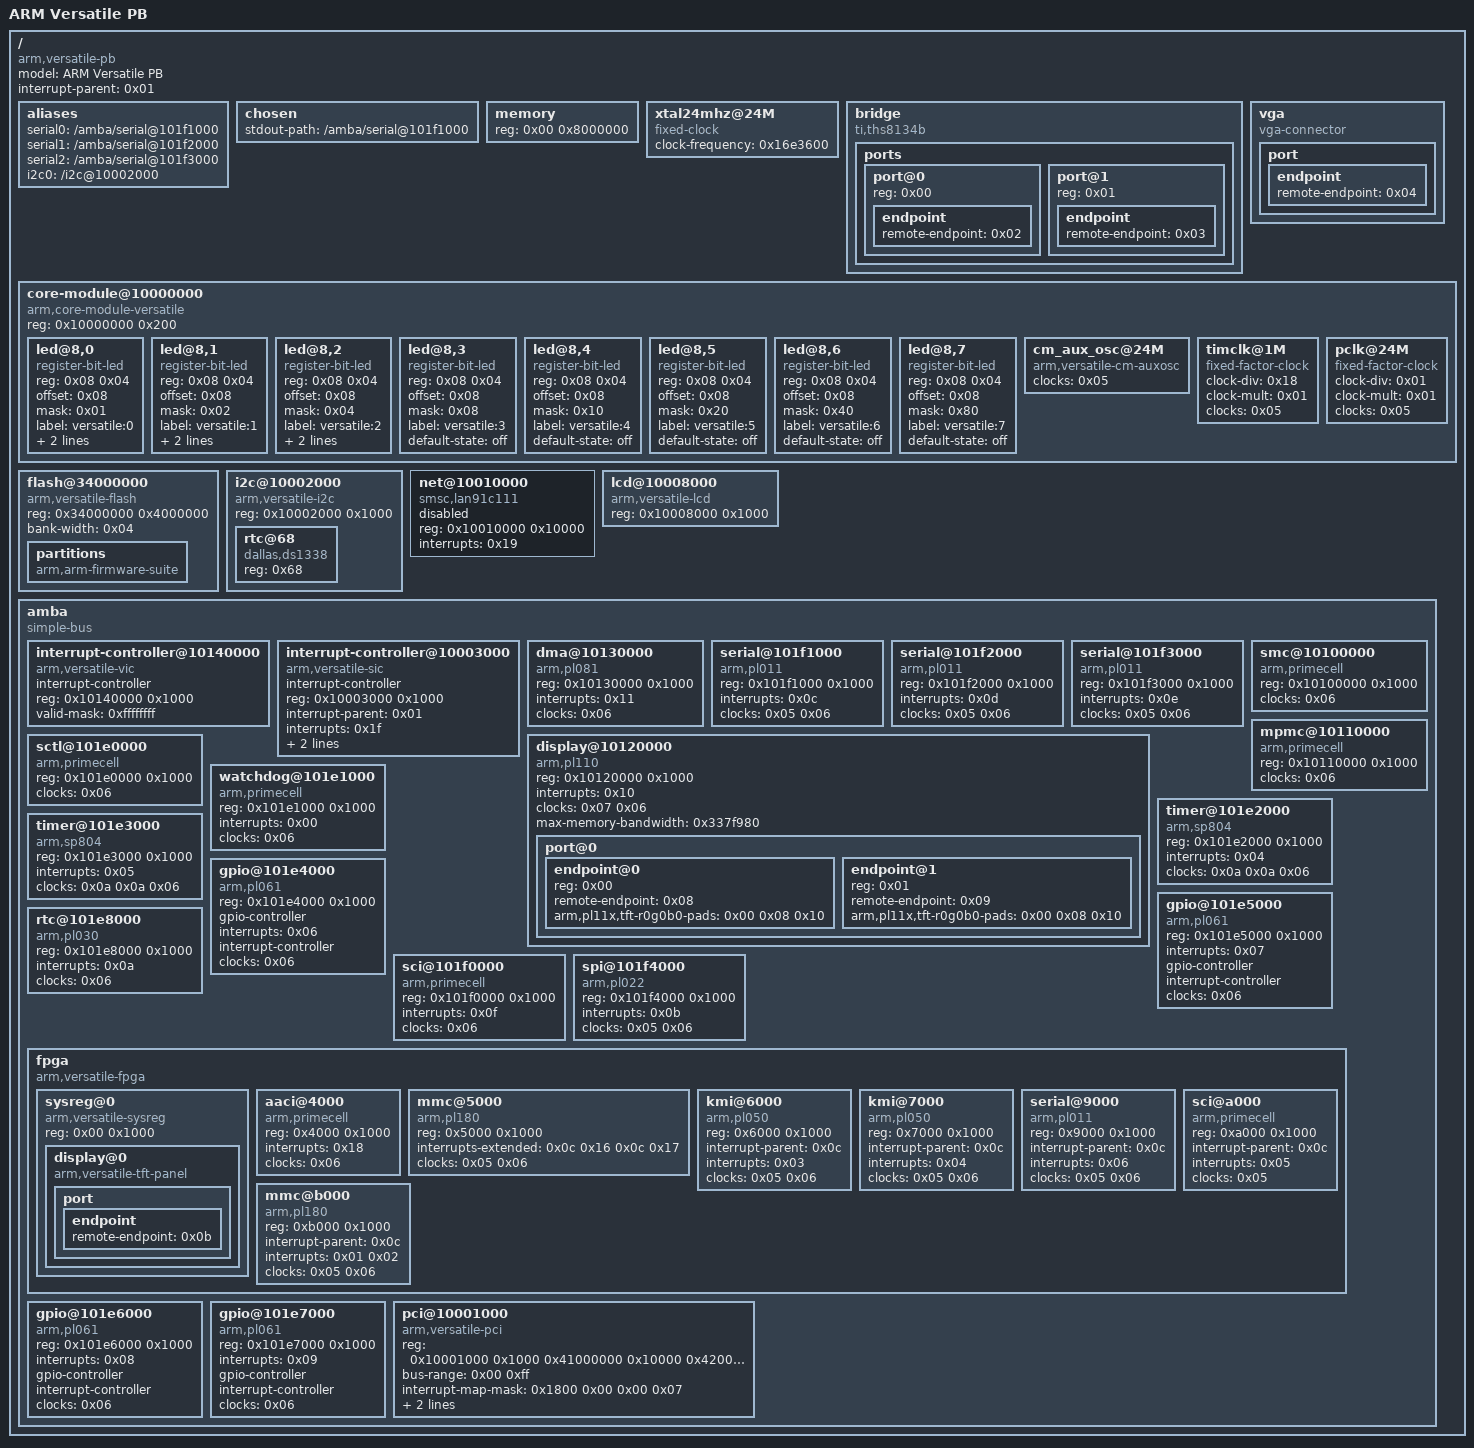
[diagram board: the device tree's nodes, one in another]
/dts-v1/;
/ {
	model = "ARM Versatile PB";
	compatible = "arm,versatile-pb";
	#address-cells = <0x01>;
	#size-cells = <0x01>;
	interrupt-parent = <0x01>;

	aliases {
		serial0 = "/amba/serial@101f1000";
		serial1 = "/amba/serial@101f2000";
		serial2 = "/amba/serial@101f3000";
		i2c0 = "/i2c@10002000";
	};

	chosen {
		stdout-path = "/amba/serial@101f1000";
	};

	memory {
		device_type = "memory";
		reg = <0x00 0x8000000>;
	};

	xtal24mhz@24M {
		#clock-cells = <0x00>;
		compatible = "fixed-clock";
		clock-frequency = <0x16e3600>;
		phandle = <0x05>;
	};

	bridge {
		compatible = "ti,ths8134b\0ti,ths8134";
		#address-cells = <0x01>;
		#size-cells = <0x00>;

		ports {
			#address-cells = <0x01>;
			#size-cells = <0x00>;

			port@0 {
				reg = <0x00>;

				endpoint {
					remote-endpoint = <0x02>;
					phandle = <0x09>;
				};
			};

			port@1 {
				reg = <0x01>;

				endpoint {
					remote-endpoint = <0x03>;
					phandle = <0x04>;
				};
			};
		};
	};

	vga {
		compatible = "vga-connector";

		port {

			endpoint {
				remote-endpoint = <0x04>;
				phandle = <0x03>;
			};
		};
	};

	core-module@10000000 {
		compatible = "arm,core-module-versatile\0syscon\0simple-mfd";
		reg = <0x10000000 0x200>;
		ranges = <0x00 0x10000000 0x200>;
		#address-cells = <0x01>;
		#size-cells = <0x01>;

		led@8,0 {
			compatible = "register-bit-led";
			reg = <0x08 0x04>;
			offset = <0x08>;
			mask = <0x01>;
			label = "versatile:0";
			linux,default-trigger = "heartbeat";
			default-state = "on";
		};

		led@8,1 {
			compatible = "register-bit-led";
			reg = <0x08 0x04>;
			offset = <0x08>;
			mask = <0x02>;
			label = "versatile:1";
			linux,default-trigger = "mmc0";
			default-state = "off";
		};

		led@8,2 {
			compatible = "register-bit-led";
			reg = <0x08 0x04>;
			offset = <0x08>;
			mask = <0x04>;
			label = "versatile:2";
			linux,default-trigger = "cpu0";
			default-state = "off";
		};

		led@8,3 {
			compatible = "register-bit-led";
			reg = <0x08 0x04>;
			offset = <0x08>;
			mask = <0x08>;
			label = "versatile:3";
			default-state = "off";
		};

		led@8,4 {
			compatible = "register-bit-led";
			reg = <0x08 0x04>;
			offset = <0x08>;
			mask = <0x10>;
			label = "versatile:4";
			default-state = "off";
		};

		led@8,5 {
			compatible = "register-bit-led";
			reg = <0x08 0x04>;
			offset = <0x08>;
			mask = <0x20>;
			label = "versatile:5";
			default-state = "off";
		};

		led@8,6 {
			compatible = "register-bit-led";
			reg = <0x08 0x04>;
			offset = <0x08>;
			mask = <0x40>;
			label = "versatile:6";
			default-state = "off";
		};

		led@8,7 {
			compatible = "register-bit-led";
			reg = <0x08 0x04>;
			offset = <0x08>;
			mask = <0x80>;
			label = "versatile:7";
			default-state = "off";
		};

		cm_aux_osc@24M {
			#clock-cells = <0x00>;
			compatible = "arm,versatile-cm-auxosc";
			clocks = <0x05>;
			phandle = <0x07>;
		};

		timclk@1M {
			#clock-cells = <0x00>;
			compatible = "fixed-factor-clock";
			clock-div = <0x18>;
			clock-mult = <0x01>;
			clocks = <0x05>;
			phandle = <0x0a>;
		};

		pclk@24M {
			#clock-cells = <0x00>;
			compatible = "fixed-factor-clock";
			clock-div = <0x01>;
			clock-mult = <0x01>;
			clocks = <0x05>;
			phandle = <0x06>;
		};
	};

	flash@34000000 {
		compatible = "arm,versatile-flash\0cfi-flash";
		reg = <0x34000000 0x4000000>;
		bank-width = <0x04>;

		partitions {
			compatible = "arm,arm-firmware-suite";
		};
	};

	i2c@10002000 {
		#address-cells = <0x01>;
		#size-cells = <0x00>;
		compatible = "arm,versatile-i2c";
		reg = <0x10002000 0x1000>;

		rtc@68 {
			compatible = "dallas,ds1338";
			reg = <0x68>;
		};
	};

	net@10010000 {
		compatible = "smsc,lan91c111";
		reg = <0x10010000 0x10000>;
		interrupts = <0x19>;
		status = "disable";
	};

	lcd@10008000 {
		compatible = "arm,versatile-lcd";
		reg = <0x10008000 0x1000>;
	};

	amba {
		compatible = "simple-bus";
		#address-cells = <0x01>;
		#size-cells = <0x01>;
		ranges;

		interrupt-controller@10140000 {
			compatible = "arm,versatile-vic";
			interrupt-controller;
			#interrupt-cells = <0x01>;
			reg = <0x10140000 0x1000>;
			valid-mask = <0xffffffff>;
			phandle = <0x01>;
		};

		interrupt-controller@10003000 {
			compatible = "arm,versatile-sic";
			interrupt-controller;
			#interrupt-cells = <0x01>;
			reg = <0x10003000 0x1000>;
			interrupt-parent = <0x01>;
			interrupts = <0x1f>;
			clear-mask = <0xffffffff>;
			valid-mask = <0x7fe003ff>;
			phandle = <0x0c>;
		};

		dma@10130000 {
			compatible = "arm,pl081\0arm,primecell";
			reg = <0x10130000 0x1000>;
			interrupts = <0x11>;
			clocks = <0x06>;
			clock-names = "apb_pclk";
		};

		serial@101f1000 {
			compatible = "arm,pl011\0arm,primecell";
			reg = <0x101f1000 0x1000>;
			interrupts = <0x0c>;
			clocks = <0x05 0x06>;
			clock-names = "uartclk\0apb_pclk";
		};

		serial@101f2000 {
			compatible = "arm,pl011\0arm,primecell";
			reg = <0x101f2000 0x1000>;
			interrupts = <0x0d>;
			clocks = <0x05 0x06>;
			clock-names = "uartclk\0apb_pclk";
		};

		serial@101f3000 {
			compatible = "arm,pl011\0arm,primecell";
			reg = <0x101f3000 0x1000>;
			interrupts = <0x0e>;
			clocks = <0x05 0x06>;
			clock-names = "uartclk\0apb_pclk";
		};

		smc@10100000 {
			compatible = "arm,primecell";
			reg = <0x10100000 0x1000>;
			clocks = <0x06>;
			clock-names = "apb_pclk";
		};

		mpmc@10110000 {
			compatible = "arm,primecell";
			reg = <0x10110000 0x1000>;
			clocks = <0x06>;
			clock-names = "apb_pclk";
		};

		display@10120000 {
			compatible = "arm,pl110\0arm,primecell";
			reg = <0x10120000 0x1000>;
			interrupts = <0x10>;
			clocks = <0x07 0x06>;
			clock-names = "clcdclk\0apb_pclk";
			max-memory-bandwidth = <0x337f980>;

			port@0 {
				#address-cells = <0x01>;
				#size-cells = <0x00>;

				endpoint@0 {
					reg = <0x00>;
					remote-endpoint = <0x08>;
					arm,pl11x,tft-r0g0b0-pads = <0x00 0x08 0x10>;
					phandle = <0x0b>;
				};

				endpoint@1 {
					reg = <0x01>;
					remote-endpoint = <0x09>;
					arm,pl11x,tft-r0g0b0-pads = <0x00 0x08 0x10>;
					phandle = <0x02>;
				};
			};
		};

		sctl@101e0000 {
			compatible = "arm,primecell";
			reg = <0x101e0000 0x1000>;
			clocks = <0x06>;
			clock-names = "apb_pclk";
		};

		watchdog@101e1000 {
			compatible = "arm,primecell";
			reg = <0x101e1000 0x1000>;
			interrupts = <0x00>;
			clocks = <0x06>;
			clock-names = "apb_pclk";
		};

		timer@101e2000 {
			compatible = "arm,sp804\0arm,primecell";
			reg = <0x101e2000 0x1000>;
			interrupts = <0x04>;
			clocks = <0x0a 0x0a 0x06>;
			clock-names = "timer0\0timer1\0apb_pclk";
		};

		timer@101e3000 {
			compatible = "arm,sp804\0arm,primecell";
			reg = <0x101e3000 0x1000>;
			interrupts = <0x05>;
			clocks = <0x0a 0x0a 0x06>;
			clock-names = "timer0\0timer1\0apb_pclk";
		};

		gpio@101e4000 {
			compatible = "arm,pl061\0arm,primecell";
			reg = <0x101e4000 0x1000>;
			gpio-controller;
			interrupts = <0x06>;
			#gpio-cells = <0x02>;
			interrupt-controller;
			#interrupt-cells = <0x02>;
			clocks = <0x06>;
			clock-names = "apb_pclk";
		};

		gpio@101e5000 {
			compatible = "arm,pl061\0arm,primecell";
			reg = <0x101e5000 0x1000>;
			interrupts = <0x07>;
			gpio-controller;
			#gpio-cells = <0x02>;
			interrupt-controller;
			#interrupt-cells = <0x02>;
			clocks = <0x06>;
			clock-names = "apb_pclk";
		};

		rtc@101e8000 {
			compatible = "arm,pl030\0arm,primecell";
			reg = <0x101e8000 0x1000>;
			interrupts = <0x0a>;
			clocks = <0x06>;
			clock-names = "apb_pclk";
		};

		sci@101f0000 {
			compatible = "arm,primecell";
			reg = <0x101f0000 0x1000>;
			interrupts = <0x0f>;
			clocks = <0x06>;
			clock-names = "apb_pclk";
		};

		spi@101f4000 {
			compatible = "arm,pl022\0arm,primecell";
			reg = <0x101f4000 0x1000>;
			interrupts = <0x0b>;
			clocks = <0x05 0x06>;
			clock-names = "sspclk\0apb_pclk";
		};

		fpga {
			compatible = "arm,versatile-fpga\0simple-bus";
			#address-cells = <0x01>;
			#size-cells = <0x01>;
			ranges = <0x00 0x10000000 0x10000>;

			sysreg@0 {
				compatible = "arm,versatile-sysreg\0syscon\0simple-mfd";
				reg = <0x00 0x1000>;

				display@0 {
					compatible = "arm,versatile-tft-panel";

					port {

						endpoint {
							remote-endpoint = <0x0b>;
							phandle = <0x08>;
						};
					};
				};
			};

			aaci@4000 {
				compatible = "arm,primecell";
				reg = <0x4000 0x1000>;
				interrupts = <0x18>;
				clocks = <0x06>;
				clock-names = "apb_pclk";
			};

			mmc@5000 {
				compatible = "arm,pl180\0arm,primecell";
				reg = <0x5000 0x1000>;
				interrupts-extended = <0x0c 0x16 0x0c 0x17>;
				clocks = <0x05 0x06>;
				clock-names = "mclk\0apb_pclk";
			};

			kmi@6000 {
				compatible = "arm,pl050\0arm,primecell";
				reg = <0x6000 0x1000>;
				interrupt-parent = <0x0c>;
				interrupts = <0x03>;
				clocks = <0x05 0x06>;
				clock-names = "KMIREFCLK\0apb_pclk";
			};

			kmi@7000 {
				compatible = "arm,pl050\0arm,primecell";
				reg = <0x7000 0x1000>;
				interrupt-parent = <0x0c>;
				interrupts = <0x04>;
				clocks = <0x05 0x06>;
				clock-names = "KMIREFCLK\0apb_pclk";
			};

			serial@9000 {
				compatible = "arm,pl011\0arm,primecell";
				reg = <0x9000 0x1000>;
				interrupt-parent = <0x0c>;
				interrupts = <0x06>;
				clocks = <0x05 0x06>;
				clock-names = "uartclk\0apb_pclk";
			};

			sci@a000 {
				compatible = "arm,primecell";
				reg = <0xa000 0x1000>;
				interrupt-parent = <0x0c>;
				interrupts = <0x05>;
				clocks = <0x05>;
				clock-names = "apb_pclk";
			};

			mmc@b000 {
				compatible = "arm,pl180\0arm,primecell";
				reg = <0xb000 0x1000>;
				interrupt-parent = <0x0c>;
				interrupts = <0x01 0x02>;
				clocks = <0x05 0x06>;
				clock-names = "mclk\0apb_pclk";
			};
		};

		gpio@101e6000 {
			compatible = "arm,pl061\0arm,primecell";
			reg = <0x101e6000 0x1000>;
			interrupts = <0x08>;
			gpio-controller;
			#gpio-cells = <0x02>;
			interrupt-controller;
			#interrupt-cells = <0x02>;
			clocks = <0x06>;
			clock-names = "apb_pclk";
		};

		gpio@101e7000 {
			compatible = "arm,pl061\0arm,primecell";
			reg = <0x101e7000 0x1000>;
			interrupts = <0x09>;
			gpio-controller;
			#gpio-cells = <0x02>;
			interrupt-controller;
			#interrupt-cells = <0x02>;
			clocks = <0x06>;
			clock-names = "apb_pclk";
		};

		pci@10001000 {
			compatible = "arm,versatile-pci";
			device_type = "pci";
			reg = <0x10001000 0x1000 0x41000000 0x10000 0x42000000 0x100000>;
			bus-range = <0x00 0xff>;
			#address-cells = <0x03>;
			#size-cells = <0x02>;
			#interrupt-cells = <0x01>;
			ranges = <0x1000000 0x00 0x00 0x43000000 0x00 0x10000 0x2000000 0x00 0x50000000 0x50000000 0x00 0x10000000 0x42000000 0x00 0x60000000 0x60000000 0x00 0x10000000>;
			interrupt-map-mask = <0x1800 0x00 0x00 0x07>;
			interrupt-map = <0x1800 0x00 0x00 0x01 0x0c 0x1c 0x1800 0x00 0x00 0x02 0x0c 0x1d 0x1800 0x00 0x00 0x03 0x0c 0x1e 0x1800 0x00 0x00 0x04 0x0c 0x1b 0x1000 0x00 0x00 0x01 0x0c 0x1b 0x1000 0x00 0x00 0x02 0x0c 0x1c 0x1000 0x00 0x00 0x03 0x0c 0x1d 0x1000 0x00 0x00 0x04 0x0c 0x1e 0x800 0x00 0x00 0x01 0x0c 0x1e 0x800 0x00 0x00 0x02 0x0c 0x1b 0x800 0x00 0x00 0x03 0x0c 0x1c 0x800 0x00 0x00 0x04 0x0c 0x1d 0x00 0x00 0x00 0x01 0x0c 0x1d 0x00 0x00 0x00 0x02 0x0c 0x1e 0x00 0x00 0x00 0x03 0x0c 0x1b 0x00 0x00 0x00 0x04 0x0c 0x1c>;
		};
	};
};
